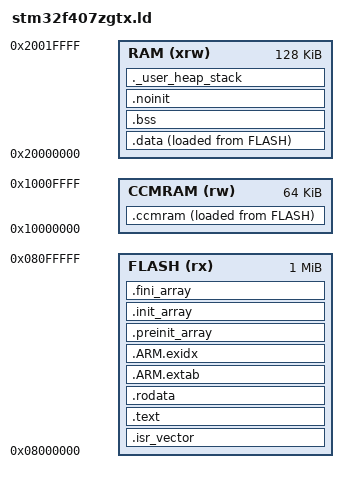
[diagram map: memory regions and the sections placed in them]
/*
 * STM32F407ZGTx 链接脚本（正点原子探索者开发板）
 * FLASH 1MB @ 0x08000000 | SRAM 128KB (112K+16K) @ 0x20000000 | CCM 64KB @ 0x10000000
 */
ENTRY(Reset_Handler)

/* 主栈顶：SRAM 末尾（全速运行 168MHz，主栈放 SRAM 而非 CCM，
 * 因为 CCM 不挂在 AHB 总线矩阵上，DMA/部分指令访问受限） */
_estack = ORIGIN(RAM) + LENGTH(RAM);

Min_Heap_Size  = 0x200;  /* 堆 512B（newlib nano，printf 等会用到） */
Min_Stack_Size = 0x400;  /* 栈 1KB */

MEMORY
{
  CCMRAM (rw) : ORIGIN = 0x10000000, LENGTH = 64K
  RAM   (xrw) : ORIGIN = 0x20000000, LENGTH = 128K
  FLASH (rx)  : ORIGIN = 0x08000000, LENGTH = 1024K
}

SECTIONS
{
  /* 中断向量表 */
  .isr_vector :
  {
    . = ALIGN(4);
    KEEP(*(.isr_vector))
    . = ALIGN(4);
  } >FLASH

  /* 代码与常量 */
  .text :
  {
    . = ALIGN(4);
    *(.text)
    *(.text*)
    *(.glue_7)
    *(.glue_7t)

    KEEP(*(.init))
    KEEP(*(.fini))

    . = ALIGN(4);
    _etext = .;
  } >FLASH

  .rodata :
  {
    . = ALIGN(4);
    *(.rodata)
    *(.rodata*)
    . = ALIGN(4);
  } >FLASH

  .ARM.extab   : { *(.ARM.extab* .gnu.linkonce.armextab.*) } >FLASH
  .ARM.exidx :
  {
    __exidx_start = .;
    *(.ARM.exidx*)
    __exidx_end = .;
  } >FLASH

  .preinit_array :
  {
    PROVIDE_HIDDEN(__preinit_array_start = .);
    KEEP(*(.preinit_array*))
    PROVIDE_HIDDEN(__preinit_array_end = .);
  } >FLASH

  .init_array :
  {
    PROVIDE_HIDDEN(__init_array_start = .);
    KEEP(*(SORT(.init_array.*)))
    KEEP(*(.init_array*))
    PROVIDE_HIDDEN(__init_array_end = .);
  } >FLASH

  .fini_array :
  {
    PROVIDE_HIDDEN(__fini_array_start = .);
    KEEP(*(SORT(.fini_array.*)))
    KEEP(*(.fini_array*))
    PROVIDE_HIDDEN(__fini_array_end = .);
  } >FLASH

  /* CCMRAM 数据段（启动时从 FLASH 拷贝） */
  _siccmram = LOADADDR(.ccmram);
  .ccmram :
  {
    . = ALIGN(4);
    _sccmram = .;
    *(.ccmram)
    *(.ccmram*)
    . = ALIGN(4);
    _eccmram = .;
  } >CCMRAM AT> FLASH

  /* 已初始化数据：运行在 RAM，值存 FLASH */
  _sidata = LOADADDR(.data);
  .data :
  {
    . = ALIGN(4);
    _sdata = .;
    *(.data)
    *(.data*)
    . = ALIGN(4);
    _edata = .;
  } >RAM AT> FLASH

  /* 未初始化数据（零初始化） */
  .bss :
  {
    . = ALIGN(4);
    _sbss = .;
    __bss_start__ = _sbss;
    *(.bss)
    *(.bss*)
    *(COMMON)
    . = ALIGN(4);
    _ebss = .;
    __bss_end__ = _ebss;
  } >RAM

  /* 不初始化段（复位后保持） */
  .noinit (NOLOAD) :
  {
    . = ALIGN(4);
    _snoinit = .;
    *(.noinit*)
    . = ALIGN(4);
    _enoinit = .;
  } >RAM

  /* 用于检查堆栈空间的占位段 */
  ._user_heap_stack (NOLOAD) :
  {
    . = ALIGN(8);
    PROVIDE(end = .);
    PROVIDE(_end = .);
    . = . + Min_Heap_Size;
    . = . + Min_Stack_Size;
    . = ALIGN(8);
  } >RAM

  /* 丢弃调试相关段 */
  /DISCARD/ :
  {
    libc.a ( * )
    libm.a ( * )
    libgcc.a ( * )
  }

  .ARM.attributes 0 : { *(.ARM.attributes) }
}
